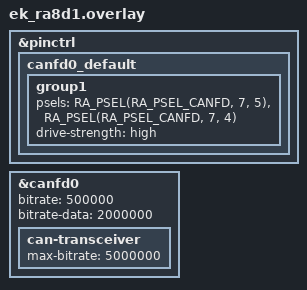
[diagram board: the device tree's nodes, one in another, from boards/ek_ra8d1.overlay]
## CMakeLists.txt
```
# SPDX-License-Identifier: Apache-2.0
#
# can_logger — integrated CAN-FD capture + CLP host link.
# Board target: ek_ra8d1. The CANFD0 pin remap (CTX0=P704 / CRX0=P705) and
# bitrates are applied automatically from boards/ek_ra8d1.overlay.
#
# clp_proto.c / clp_proto.h are shared verbatim with apps/usb_cdc (the CLP
# protocol codec is transport-agnostic by design — see docs/clp_protocol.md).
# They are referenced in place rather than copied so there is a single source
# of truth; clp_uart.c is the UART-specific transport glue (cf. usb_cdc's
# usb_link.c for the CDC-ACM one).

cmake_minimum_required(VERSION 3.28.0)

find_package(Zephyr REQUIRED HINTS $ENV{ZEPHYR_BASE})
project(can_logger)

target_include_directories(app PRIVATE
  include
  ${CMAKE_CURRENT_SOURCE_DIR}/../usb_cdc/include
)
target_sources(app PRIVATE
  src/main.c
  src/can_iface.c
  src/clp_uart.c
  ${CMAKE_CURRENT_SOURCE_DIR}/../usb_cdc/src/clp_proto.c
)
```

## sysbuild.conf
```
# Phase 3 — sysbuild configuration for apps/can_logger.
# Only consumed when the app is built with `west build --sysbuild`; a plain
# `west build apps/can_logger` ignores this file and builds exactly as in
# Phase 2A (no bootloader, links at flash0 base 0x02000000).
#
# Every SB_CONFIG_* symbol below was checked against this checkout:
#   SB_CONFIG_BOOTLOADER_MCUBOOT            -> zephyr/share/sysbuild/images/bootloader/Kconfig
#   SB_CONFIG_MCUBOOT_MODE_OVERWRITE_ONLY   -> same file, choice MCUBOOT_MODE
#   SB_CONFIG_BOOT_SIGNATURE_TYPE_ECDSA_P256-> same file, choice BOOT_SIGNATURE_TYPE
#
# Mode = OVERWRITE_ONLY (not the sysbuild default SWAP_USING_OFFSET) because
# the RA8D1 on-chip code flash (flash0) has write-block-size = 128, and
# MCUboot's bootutil_public.h hard-asserts
#   MCUBOOT_BOOT_MAX_ALIGN >= 8 && <= 32   "for SWAP upgrade modes"
# (CONFIG_MCUBOOT_BOOT_MAX_ALIGN defaults to the chosen flash write-block-size
# -> 128 here). OVERWRITE_ONLY does not trip that assert. See STATE.md.

SB_CONFIG_BOOTLOADER_MCUBOOT=y
SB_CONFIG_MCUBOOT_MODE_OVERWRITE_ONLY=y

# ECDSA P-256 image signing: smaller verify code than RSA-2048 on Cortex-M85,
# and the private PEM that ships with the mcuboot module
# ($ZEPHYR_MCUBOOT_MODULE_DIR/root-ec-p256.pem) is used automatically until we
# supply our own key via SB_CONFIG_BOOT_SIGNATURE_KEY_FILE. This is the hook
# for a project signing key (see STATE.md "MCUboot / SecOC" note).
SB_CONFIG_BOOT_SIGNATURE_TYPE_ECDSA_P256=y
```

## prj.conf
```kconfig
# can_logger — integrated CAN-FD capture + CLP host link (Phase 5 follow-on).
#
# The Phase 2A CAN-FD module (can_iface.c) now feeds the Phase 2C CLP protocol
# (clp_proto.c, shared from apps/usb_cdc) over a UART transport (clp_uart.c).
# Live RX frames go to the host as CLP_MSG_CAN_RX; the host can request a
# transmit with CLP_MSG_CAN_TX. Every symbol below was checked against the
# workspace before being added.
#
#   CONFIG_CAN / _CAN_FD_MODE / _CAN_RENESAS_RA_CANFD -> drivers/can/Kconfig*
#        (unchanged from Phase 2A). NOT CONFIG_CAN_RX_TIMESTAMP — the
#        renesas,ra-canfd driver does not implement it; we software-timestamp
#        in the RX ISR (can_iface.c).
#   CONFIG_COBS   -> lib/utils/Kconfig  (COBS framing, <zephyr/data/cobs.h>)
#   CONFIG_CRC    -> subsys/crc/Kconfig (crc16_ccitt() for CLP CRC-16/X-25).
#        CONFIG_CRC_HW_HANDLER forced off — clp_proto.c uses the SW routine and
#        we don't want the on-chip CRC driver pulled in.
#   CONFIG_RING_BUFFER -> lib/os/Kconfig (tx/rx byte rings in clp_uart.c)
#   CONFIG_UART_INTERRUPT_DRIVEN -> drivers/serial/Kconfig; the uart9 driver is
#        renesas,ra8-uart-sci-b (uart_renesas_ra8_sci_b.c) which implements the
#        fifo_fill / irq_tx_ready / irq_rx_ready / irq_callback_set API.
#   CONFIG_POLL -> kernel/Kconfig (k_poll is not used; k_msgq + k_sem only).

CONFIG_CAN=y
CONFIG_CAN_FD_MODE=y
CONFIG_CAN_RENESAS_RA_CANFD=y

CONFIG_SERIAL=y
CONFIG_UART_INTERRUPT_DRIVEN=y
CONFIG_RING_BUFFER=y
CONFIG_COBS=y
CONFIG_CRC=y
CONFIG_CRC_HW_HANDLER=n

# --- COM12 (J-Link VCOM = uart9) is handed over to raw CLP binary framing ---
# The UART console driver and the UART log backend would both write ASCII onto
# the same wire and corrupt the CLP byte stream, so both are disabled. Zephyr
# logging + printk are routed to SEGGER RTT instead (view with J-Link RTT
# Viewer / `JLinkRTTClient`), which keeps a debug channel without touching COM12.
CONFIG_UART_CONSOLE=n
CONFIG_LOG=y
CONFIG_LOG_DEFAULT_LEVEL=3
CONFIG_LOG_BACKEND_UART=n
CONFIG_USE_SEGGER_RTT=y
CONFIG_LOG_BACKEND_RTT=y
CONFIG_RTT_CONSOLE=y
CONFIG_SEGGER_RTT_BUFFER_SIZE_UP=4096
# Drop log records when no RTT viewer is draining the buffer (headless bench
# runs) instead of stalling on every message.
CONFIG_LOG_BACKEND_RTT_MODE_DROP=y

# clp_uart.c encodes CLP frames (COBS + CRC, up to ~90 B) on the caller stack;
# the CAN RX ISR only does a k_msgq_put, so the heavy work is in threads. 4 KiB
# main stack matches the other apps and covers the boot-time HELLO encode.
CONFIG_MAIN_STACK_SIZE=4096
```

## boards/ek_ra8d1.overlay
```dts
/*
 * App-local devicetree overlay for apps/can_logger on the EK-RA8D1.
 * Zephyr auto-applies <app>/boards/<board>.overlay by filename.
 *
 * Mirrors the project overlay D:/BITS_ASSIGNMENTS/ESD/SITUATIONAL_LEARNING/
 * boards/ek_ra8d1.overlay (kept in sync by hand) and additionally sets the
 * CAN-FD bitrates for this app.
 *
 * CANFD0 pins (see STATE.md "CANFD0 pin decision" + its RETRACTION for the
 * full rationale):
 *     CTX0 (CAN TX, MCU -> transceiver TXD) = P704
 *     CRX0 (CAN RX, transceiver RXD -> MCU) = P705
 * This is the Renesas FSP default pair, and matches the physical breadboard
 * wiring as built.
 *
 * The Phase 1 choice of P203/P202 is RETRACTED (2026-08-31): our part
 * R7FA8D1BHECBD (package PLBG0224GD-A) is the MIPI variant per datasheet
 * Table 1.13, so P202-P205 are permanently MIPI_CL_P/N + MIPI_DL0_P/N and
 * do not exist as GPIO/CANFD pins at all. The earlier "confirmation" read
 * the datasheet's "BGA224 without MIPI" column by mistake.
 *
 * TRADE-OFF ACCEPTED: P704/P705 are RMII0_RX_ER_B / RMII0_CRS_DV_B in the
 * board's ETHERNET-B mux and are bus-switch-routed to the Ethernet PHY in
 * hardware, so CAN-FD and on-chip Ethernet are mutually exclusive on this
 * board. Project decision: sequential use modes (capture over CAN, retrieve
 * over Ethernet afterwards), not simultaneous.
 *
 * Transceiver STB is hard-wired to GND (normal mode), so there is no
 * enable/standby GPIO entry here on purpose.
 */

#include <zephyr/dt-bindings/pinctrl/renesas/pinctrl-ra.h>

&pinctrl {
	/* Overrides the same-named node in
	 * zephyr/boards/renesas/ek_ra8d1/ek_ra8d1-pinctrl.dtsi; psels replaced.
	 *
	 * Encoding verified against pinctrl-ra.h:144 --
	 * RA_PSEL(psel,port,pin) = 1<<13 | psel<<8 | pin<<4 | port<<0,
	 * RA_PSEL_CANFD = 0x10. So P704 -> 0x3047, P705 -> 0x3057.
	 */
	canfd0_default: canfd0_default {
		group1 {
			/* CRX0 CTX0 */
			psels = <RA_PSEL(RA_PSEL_CANFD, 7, 5)>,   /* CRX0 -> P705 */
				<RA_PSEL(RA_PSEL_CANFD, 7, 4)>;   /* CTX0 -> P704 */
			drive-strength = "high";
		};
	};
};

&canfd0 {
	/* Arbitration phase 500 kbit/s, FD data phase 2 Mbit/s — common
	 * automotive CAN-FD rates and safely within any CAN-FD transceiver.
	 * Sample points left unset -> driver auto-selects (87.5% / 80% / 75%).
	 */
	bitrate = <500000>;
	bitrate-data = <2000000>;

	/* Passive external transceiver on the breadboard (STB tied to GND).
	 * max-bitrate documents the data-phase ceiling used for bitrate
	 * validation; tighten to the real transceiver datasheet once known.
	 */
	can-transceiver {
		max-bitrate = <5000000>;
	};
};
```

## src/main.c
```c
/*
 * SPDX-License-Identifier: Apache-2.0
 *
 * can_logger — integrated entry point.
 *
 * Wires the Phase 2A CAN-FD module (can_iface.c) to the Phase 2C CLP protocol
 * (clp_proto.c) over a UART transport (clp_uart.c):
 *
 *     canfd0 RX ISR ──▶ on_can_rx() ──▶ k_msgq ──▶ pump_thread ──▶ CLP_MSG_CAN_RX ──▶ COM12
 *     COM12 ──▶ CLP_MSG_CAN_TX ──▶ on_tx_request() ──▶ can_iface_send() ──▶ canfd0 TX
 *                                                  └─▶ CLP_MSG_CAN_TX_ACK ──▶ COM12
 *     pump_thread also emits CLP_MSG_STATUS ~1 Hz.
 *
 * The RX ISR does only a k_msgq_put so interrupt latency stays low; all CLP
 * encoding happens in pump_thread / rx_thread context.
 *
 * "Interrupt + NVIC" report deliverable: the RX path is canfd0 RX vector
 * (NVIC IRQ 45, prio 12) -> can_iface_rx_isr -> on_can_rx. See can_iface.c.
 */

#include <errno.h>
#include <string.h>

#include <zephyr/kernel.h>
#include <zephyr/logging/log.h>

#include "can_iface.h"
#include "clp_uart.h"

LOG_MODULE_REGISTER(main, LOG_LEVEL_INF);

/* Boot self-transmit: a bench convenience that proves the TX path on power-up.
 * OFF by default: a logger should not inject traffic onto a bus that may not
 * be live yet. With no peer ACKing, the RA controller auto-retransmits (no
 * CAN_MODE_ONE_SHOT on this driver) and one frame becomes a sustained error
 * storm -> BUS_OFF. Set to 1 only for bench TX testing with a peer present.
 */
#define BOOT_TX_SELFTEST 0
/* If BOOT_TX_SELFTEST: CLASSIC frame only (the bench PCAN-USB is classic-only;
 * an FD/BRS frame there storms even harder). Flip to 1 with FD-capable gear.
 */
#define BOOT_TX_USE_FD 0

/* CAN RX ISR -> pump_thread hand-off. 64 * sizeof(canlog_frame) ~= 5 KiB. */
K_MSGQ_DEFINE(can_rx_msgq, sizeof(struct canlog_frame), 64, 4);

static atomic_t stat_rx_msgq_drops;   /* CAN faster than the pump could drain */
static atomic_t stat_tx_requests;     /* CLP_MSG_CAN_TX accepted from the host */

/* -------------------------------------------------------------------------- */
/* Flag translation: Zephyr CAN_FRAME_* <-> CLP_CANF_*                         */
/*                                                                            */
/* clp_proto.h's comment claims the bit positions line up 1:1 with Zephyr's,  */
/* but they do NOT (CAN_FRAME_IDE=BIT(0) vs CLP_CANF_IDE=BIT(3), etc.). The    */
/* usb_cdc self-test never noticed because it only round-trips CLP<->CLP. An   */
/* explicit map is the integration point where that matters.                  */
/* -------------------------------------------------------------------------- */

static uint8_t clp_flags_from_can(uint8_t canf)
{
	uint8_t o = 0U;

	if (canf & CAN_FRAME_FDF) {
		o |= CLP_CANF_FDF;
	}
	if (canf & CAN_FRAME_BRS) {
		o |= CLP_CANF_BRS;
	}
	if (canf & CAN_FRAME_ESI) {
		o |= CLP_CANF_ESI;
	}
	if (canf & CAN_FRAME_IDE) {
		o |= CLP_CANF_IDE;
	}
	if (canf & CAN_FRAME_RTR) {
		o |= CLP_CANF_RTR;
	}
	return o;
}

static uint8_t can_flags_from_clp(uint8_t clpf)
{
	uint8_t o = 0U;

	if (clpf & CLP_CANF_FDF) {
		o |= CAN_FRAME_FDF;
	}
	if (clpf & CLP_CANF_BRS) {
		o |= CAN_FRAME_BRS;
	}
	if (clpf & CLP_CANF_ESI) {
		o |= CAN_FRAME_ESI;
	}
	if (clpf & CLP_CANF_IDE) {
		o |= CAN_FRAME_IDE;
	}
	if (clpf & CLP_CANF_RTR) {
		o |= CAN_FRAME_RTR;
	}
	return o;
}

/* -------------------------------------------------------------------------- */
/* CAN RX  (ISR context - keep it to the k_msgq_put)                          */
/* -------------------------------------------------------------------------- */

static void on_can_rx(const struct canlog_frame *frame, void *user_data)
{
	ARG_UNUSED(user_data);

	if (k_msgq_put(&can_rx_msgq, frame, K_NO_WAIT) != 0) {
		atomic_inc(&stat_rx_msgq_drops);
	}
}

/* -------------------------------------------------------------------------- */
/* CLP_MSG_CAN_TX from the host  (rx_thread context)                          */
/* -------------------------------------------------------------------------- */

static void on_tx_request(const struct clp_can_frame *req, void *user_data)
{
	ARG_UNUSED(user_data);

	struct canlog_frame tx = {
		.id = req->can_id,
		.dlc = req->dlc,
		.flags = can_flags_from_clp(req->flags),
	};
	const uint8_t n = can_dlc_to_bytes(req->dlc);
	int ret;

	memcpy(tx.data, req->data, MIN(n, (uint8_t)sizeof(tx.data)));

	ret = can_iface_send(&tx, K_MSEC(50));
	if (ret == 0) {
		atomic_inc(&stat_tx_requests);
	} else {
		LOG_WRN("host CAN_TX id=0x%x -> can_iface_send %d", req->can_id, ret);
	}

	struct clp_tx_ack ack = {
		.tag = req->tag,
		.status = (int16_t)ret,
		.timestamp = (uint64_t)k_uptime_ticks(),
	};
	(void)clp_uart_send_tx_ack(&ack);
}

/* -------------------------------------------------------------------------- */
/* Pump thread: msgq -> CLP_MSG_CAN_RX, plus ~1 Hz CLP_MSG_STATUS             */
/* -------------------------------------------------------------------------- */

static void send_status(void)
{
	enum can_state bus_state = CAN_STATE_ERROR_ACTIVE;
	struct can_bus_err_cnt err = { 0 };
	uint32_t tx_frames = 0, tx_drops = 0, crc_err = 0, frm_err = 0;

	(void)can_iface_state(&bus_state, &err);
	clp_uart_get_counters(&tx_frames, &tx_drops, &crc_err, &frm_err);

	struct clp_status st = {
		.bus_state = (uint8_t)bus_state,
		.rx_frames = tx_frames,
		.tx_frames = (uint32_t)atomic_get(&stat_tx_requests),
		.rx_drops = tx_drops + (uint32_t)atomic_get(&stat_rx_msgq_drops),
		.tx_err_cnt = err.tx_err_cnt,
		.rx_err_cnt = err.rx_err_cnt,
	};

	(void)clp_uart_send_status(&st);
}

static void pump_thread(void *a, void *b, void *c)
{
	ARG_UNUSED(a);
	ARG_UNUSED(b);
	ARG_UNUSED(c);

	int64_t last_status = k_uptime_get();
	unsigned int status_ticks = 0;

	for (;;) {
		struct canlog_frame f;

		if (k_msgq_get(&can_rx_msgq, &f, K_MSEC(500)) == 0) {
			struct clp_can_frame cf = {
				.can_id = f.id,
				.flags = clp_flags_from_can(f.flags),
				.dlc = f.dlc,
				.tag = 0U,
				.timestamp = f.timestamp,
			};

			memcpy(cf.data, f.data, sizeof(cf.data));
			(void)clp_uart_send_can_rx(&cf);
		}

		if (k_uptime_get() - last_status >= 1000) {
			last_status = k_uptime_get();
			send_status();
			/* Re-announce every 5 s so a host attaching mid-run
			 * still learns the fw version (HELLO is otherwise
			 * boot-only).
			 */
			if (++status_ticks % 5U == 0U) {
				clp_uart_send_hello();
			}
		}
	}
}

static K_THREAD_STACK_DEFINE(pump_stack, 2048);
static struct k_thread pump_data;

/* -------------------------------------------------------------------------- */

int main(void)
{
	int ret;

	ret = can_iface_init();
	if (ret != 0) {
		LOG_ERR("can_iface_init failed: %d", ret);
		return 0;
	}
	can_iface_set_rx_handler(on_can_rx, NULL);

	ret = clp_uart_init();
	if (ret != 0) {
		LOG_ERR("clp_uart_init failed: %d", ret);
		return 0;
	}
	clp_uart_set_tx_handler(on_tx_request, NULL);

	k_thread_create(&pump_data, pump_stack, K_THREAD_STACK_SIZEOF(pump_stack),
			pump_thread, NULL, NULL, NULL,
			K_PRIO_PREEMPT(8), 0, K_NO_WAIT);
	k_thread_name_set(&pump_data, "clp_pump");

#if BOOT_TX_SELFTEST
	/* Bench-only: prove the TX path on power-up. Needs a peer ACKing. */
	struct canlog_frame boot_tx = {
		.id = 0x123,
		.dlc = 8,
#if BOOT_TX_USE_FD
		.flags = CAN_FRAME_FDF | CAN_FRAME_BRS,
#else
		.flags = 0,
#endif
	};

	for (uint8_t i = 0; i < 8; i++) {
		boot_tx.data[i] = i;
	}

	ret = can_iface_send(&boot_tx, K_MSEC(100));
	if (ret != 0) {
		LOG_WRN("boot self-TX returned %d (no bus / no ACK?)", ret);
	}
#endif

	LOG_INF("can_logger integrated: CAN-FD <-> CLP on the console UART");
	return 0;
}
```

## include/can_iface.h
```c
/*
 * SPDX-License-Identifier: Apache-2.0
 *
 * Phase 2A — self-contained CAN-FD interface for canfd0 on the EK-RA8D1.
 *
 * Wraps the Zephyr native CAN controller API (zephyr/drivers/can.h) for the
 * on-chip Renesas RA CAN-FD controller (compatible "renesas,ra-canfd",
 * channel 0). The transceiver is external and passive (STB hard-wired to
 * GND); pin routing CTX0=P203 / CRX0=P202 comes from the board overlay.
 *
 * Build-only in this phase: no board attached, nothing is flashed or run.
 */

#ifndef CAN_LOGGER_CAN_IFACE_H_
#define CAN_LOGGER_CAN_IFACE_H_

#include <stdint.h>
#include <zephyr/kernel.h>
#include <zephyr/drivers/can.h>

/**
 * @brief One captured/queued CAN(-FD) frame.
 *
 * Deliberately a superset of the fields the university report asks for:
 * ID, DLC, flags, data, timestamp.
 *
 * @note @p data is sized to CAN_MAX_DLEN, which is 64 when CONFIG_CAN_FD_MODE
 *       is enabled and 8 otherwise (see zephyr/include/zephyr/drivers/can.h).
 * @note @p timestamp is a *software* timestamp (k_uptime_ticks()) sampled
 *       inside the RX interrupt callback. The renesas,ra-canfd driver does
 *       not implement CONFIG_CAN_RX_TIMESTAMP, so no hardware bit-time
 *       timestamp is available on this SoC.
 */
struct canlog_frame {
	/** Standard (<= CAN_STD_ID_MASK) or extended (<= CAN_EXT_ID_MASK) ID. */
	uint32_t id;
	/** Raw Data Length Code. Byte count = can_dlc_to_bytes(dlc). */
	uint8_t dlc;
	/** Frame flags: CAN_FRAME_IDE | _RTR | _FDF | _BRS | _ESI. */
	uint8_t flags;
	/** Payload. Valid bytes = can_dlc_to_bytes(dlc). */
	uint8_t data[CAN_MAX_DLEN];
	/** k_uptime_ticks() captured in the RX ISR callback. */
	uint64_t timestamp;
};

/**
 * @brief RX handler, invoked from the CAN RX interrupt callback (ISR context).
 *
 * Keep it short and non-blocking. See can_iface.c for the "Interrupt + NVIC"
 * notes (canfd0 RX vector = NVIC IRQ 45, priority 12).
 */
typedef void (*canlog_rx_handler_t)(const struct canlog_frame *frame, void *user_data);

/**
 * @brief Configure canfd0 for CAN-FD, install the standard/extended/FD RX
 *        filters and start the controller.
 *
 * @retval 0        on success
 * @retval -ENODEV  canfd0 device not ready
 * @retval -ENOTSUP controller does not advertise CAN_MODE_FD
 * @retval <0       errno from can_set_mode()/can_add_rx_filter()/can_start()
 */
int can_iface_init(void);

/**
 * @brief Register the application RX handler (called in ISR context).
 *
 * @retval 0 always. Pass NULL to detach.
 */
int can_iface_set_rx_handler(canlog_rx_handler_t handler, void *user_data);

/**
 * @brief Queue a frame for transmission on canfd0 (non-blocking).
 *
 * Fills a struct can_frame from @p frame and calls can_send() with an
 * internal completion callback, so this never blocks on bus arbitration.
 *
 * @param frame   frame to send (id/dlc/flags/data are used)
 * @param timeout wait for a free TX mailbox, or K_NO_WAIT / K_FOREVER
 * @retval 0 on success, negative errno from can_send() otherwise
 */
int can_iface_send(const struct canlog_frame *frame, k_timeout_t timeout);

/**
 * @brief Thin pass-through to can_get_state() for canfd0.
 */
int can_iface_state(enum can_state *state, struct can_bus_err_cnt *err_cnt);

#endif /* CAN_LOGGER_CAN_IFACE_H_ */
```

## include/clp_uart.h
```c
/*
 * SPDX-License-Identifier: Apache-2.0
 *
 * CLP transport glue for a plain hardware UART (the J-Link VCOM on COM12,
 * chosen zephyr,console = &uart9 on the EK-RA8D1).
 *
 * Mirrors apps/usb_cdc/src/usb_link.c (the CDC-ACM transport) but for an
 * interrupt-driven SCI UART:
 *   - TX: clp_uart_send_*() encode a COBS-framed CLP frame on the caller's
 *     stack and push the bytes into an outbound ring buffer under a spinlock.
 *     Callable from any context including the CAN RX ISR. Lossy by design:
 *     a full ring drops the frame and bumps a counter, never blocks.
 *   - RX: the UART ISR copies received bytes into an inbound ring and wakes a
 *     worker thread, which feeds clp_parser and forwards decoded
 *     CLP_MSG_CAN_TX requests to the registered handler (thread context).
 *
 * There is no DTR / connect concept on a bare UART, so a HELLO is sent once at
 * init and the caller is expected to emit periodic CLP_MSG_STATUS frames so a
 * host that attaches late can resync (COBS guarantees resync at the next 0x00).
 */

#ifndef CAN_LOGGER_CLP_UART_H_
#define CAN_LOGGER_CLP_UART_H_

#include <stdbool.h>
#include <stdint.h>

#include "clp_proto.h"

#ifdef __cplusplus
extern "C" {
#endif

/** Invoked in worker-thread context for each CLP_MSG_CAN_TX received. */
typedef void (*clp_uart_tx_request_cb_t)(const struct clp_can_frame *req,
					 void *user_data);

/**
 * @brief Take over the console UART, start the RX worker, queue a HELLO.
 *
 * @retval 0        success
 * @retval -ENODEV  the UART device is not ready
 */
int clp_uart_init(void);

/** Register the CLP_MSG_CAN_TX handler. Pass NULL to detach. */
void clp_uart_set_tx_handler(clp_uart_tx_request_cb_t cb, void *user_data);

/**
 * @brief Queue a HELLO frame. Sent once by clp_uart_init(); call again
 *        periodically so a host that attaches mid-run learns the fw version.
 */
void clp_uart_send_hello(void);

/**
 * @brief Queue a received CAN frame for the host as CLP_MSG_CAN_RX.
 *
 * Non-blocking. @retval 0 queued, -ENOSPC dropped (ring full), <0 encode error.
 */
int clp_uart_send_can_rx(const struct clp_can_frame *f);

/** Queue a CLP_MSG_CAN_TX_ACK. Same semantics as clp_uart_send_can_rx(). */
int clp_uart_send_tx_ack(const struct clp_tx_ack *ack);

/** Queue a CLP_MSG_STATUS. Same semantics as clp_uart_send_can_rx(). */
int clp_uart_send_status(const struct clp_status *st);

/** Snapshot of link counters (any pointer may be NULL). */
void clp_uart_get_counters(uint32_t *tx_frames, uint32_t *tx_drops,
			   uint32_t *crc_errors, uint32_t *framing_errors);

#ifdef __cplusplus
}
#endif

#endif /* CAN_LOGGER_CLP_UART_H_ */
```

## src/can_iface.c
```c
/*
 * SPDX-License-Identifier: Apache-2.0
 *
 * Phase 2A — CAN-FD interface module for canfd0 (build-only).
 *
 * All Zephyr CAN API used here was verified against
 * zephyr/include/zephyr/drivers/can.h and the controller driver
 * drivers/can/can_renesas_ra.c in this workspace (not from memory):
 *
 *   struct can_frame  { uint32_t id; uint8_t dlc; uint8_t flags;
 *                       uint16_t timestamp/reserved; uint8_t data[CAN_MAX_DLEN]; ... }
 *   struct can_filter { uint32_t id; uint32_t mask; uint8_t flags; }   // flags: only CAN_FILTER_IDE
 *   int  can_set_mode(const struct device *, can_mode_t);
 *   int  can_start(const struct device *);
 *   int  can_send(const struct device *, const struct can_frame *,
 *                 k_timeout_t, can_tx_callback_t, void *user_data);
 *   int  can_add_rx_filter(const struct device *, can_rx_callback_t,
 *                          void *user_data, const struct can_filter *);   // returns filter_id
 *   int  can_get_capabilities(const struct device *, can_mode_t *);
 *   int  can_get_core_clock(const struct device *, uint32_t *);
 *   int  can_get_state(const struct device *, enum can_state *, struct can_bus_err_cnt *);
 *   typedef void (*can_rx_callback_t)(const struct device *, struct can_frame *, void *);
 *   typedef void (*can_tx_callback_t)(const struct device *, int error, void *);
 */

#include <string.h>

#include <zephyr/kernel.h>
#include <zephyr/device.h>
#include <zephyr/drivers/can.h>
#include <zephyr/logging/log.h>

#include "can_iface.h"

LOG_MODULE_REGISTER(can_iface, LOG_LEVEL_INF);

/*
 * canfd0 is the board's chosen CAN bus:
 *   zephyr,canbus = &canfd0;   (zephyr/boards/renesas/ek_ra8d1/ek_ra8d1.dts)
 * Channel 0, compatible "renesas,ra-canfd". Its interrupts (from
 * zephyr/dts/arm/renesas/ra/ra8/ra8x1.dtsi) are:
 *   err = 43, tx = 44, rx = 45   (all at priority 12)
 */
#define CANFD0_NODE DT_CHOSEN(zephyr_canbus)
BUILD_ASSERT(DT_NODE_HAS_STATUS(CANFD0_NODE, okay),
	     "chosen zephyr,canbus (canfd0) is not enabled");

static const struct device *const canfd0 = DEVICE_DT_GET(CANFD0_NODE);

/* ---------------------------------------------------------------------------
 * "Interrupt + NVIC" deliverable (university report)
 * ---------------------------------------------------------------------------
 * The Renesas RA CAN-FD driver connects the channel-0 RX FIFO vector with:
 *
 *   IRQ_CONNECT(DT_INST_IRQ_BY_NAME(index, rx, irq),          // == 45 for canfd0
 *               DT_INST_IRQ_BY_NAME(index, rx, priority),      // == 12
 *               canfd_common_fifo_rx_isr, NULL, 0);
 *   irq_enable(DT_INST_IRQ_BY_NAME(index, rx, irq));           // enable NVIC line 45
 *
 * (drivers/can/can_renesas_ra.c, CAN_RENESAS_RA_INIT()).
 *
 * On a received frame the Cortex-M85 NVIC takes exception for IRQ 45,
 * canfd_common_fifo_rx_isr() runs, the FSP posts CAN_EVENT_RX_COMPLETE, and
 * the driver calls the callback we registered with can_add_rx_filter() -
 * can_iface_rx_isr() below - still in interrupt context. That callback is
 * this project's interrupt-service path for CAN reception.
 * ------------------------------------------------------------------------- */

static canlog_rx_handler_t rx_handler;
static void *rx_handler_user_data;
static int rx_filter_ids[3] = { -1, -1, -1 };

/* RX interrupt callback (ISR context - keep it short, no blocking calls). */
static void can_iface_rx_isr(const struct device *dev, struct can_frame *frame, void *user_data)
{
	ARG_UNUSED(dev);
	ARG_UNUSED(user_data);

	canlog_rx_handler_t handler = rx_handler;

	if (handler == NULL) {
		return;
	}

	struct canlog_frame out = {
		.id = frame->id,
		.dlc = frame->dlc,
		.flags = frame->flags,
		/* Software timestamp: the renesas,ra-canfd driver does not
		 * implement CONFIG_CAN_RX_TIMESTAMP, so frame->timestamp is
		 * meaningless. k_uptime_ticks() is ISR-safe.
		 */
		.timestamp = (uint64_t)k_uptime_ticks(),
	};

	const uint8_t len = can_dlc_to_bytes(frame->dlc);

	memcpy(out.data, frame->data, MIN(len, (uint8_t)sizeof(out.data)));

	handler(&out, rx_handler_user_data);
}

/* TX completion callback (ISR context). Non-blocking send path. */
static void can_iface_tx_done(const struct device *dev, int error, void *user_data)
{
	ARG_UNUSED(dev);
	ARG_UNUSED(user_data);

	if (error != 0) {
		LOG_WRN("CAN TX completion error: %d", error);
	}
}

int can_iface_set_rx_handler(canlog_rx_handler_t handler, void *user_data)
{
	/* Pointer-sized stores; the RX ISR reads a local snapshot of
	 * rx_handler first. Set this before traffic starts.
	 */
	rx_handler_user_data = user_data;
	rx_handler = handler;
	return 0;
}

int can_iface_send(const struct canlog_frame *frame, k_timeout_t timeout)
{
	if (frame == NULL) {
		return -EINVAL;
	}

	struct can_frame tx = {
		.id = frame->id,
		.dlc = frame->dlc,
		.flags = frame->flags,
	};

	const uint8_t len = can_dlc_to_bytes(frame->dlc);

	memcpy(tx.data, frame->data, MIN(len, (uint8_t)sizeof(tx.data)));

	/* Non-blocking: a non-NULL callback makes can_send() return as soon as
	 * the frame is queued (zephyr/include/zephyr/drivers/can.h).
	 */
	return can_send(canfd0, &tx, timeout, can_iface_tx_done, NULL);
}

int can_iface_state(enum can_state *state, struct can_bus_err_cnt *err_cnt)
{
	return can_get_state(canfd0, state, err_cnt);
}

int can_iface_init(void)
{
	int ret;
	uint32_t core_clock = 0;
	can_mode_t caps = 0;

	if (!device_is_ready(canfd0)) {
		LOG_ERR("canfd0 device not ready");
		return -ENODEV;
	}

	ret = can_get_capabilities(canfd0, &caps);
	if (ret != 0) {
		LOG_ERR("can_get_capabilities: %d", ret);
		return ret;
	}
	if ((caps & CAN_MODE_FD) == 0) {
		LOG_ERR("canfd0 does not advertise CAN_MODE_FD (caps=0x%08x)", caps);
		return -ENOTSUP;
	}

	/* CAN-FD, normal (not loopback/listen-only). Bitrates come from the
	 * devicetree (bitrate / bitrate-data in boards/ek_ra8d1.overlay), so
	 * no can_set_bitrate() call is needed here.
	 */
	ret = can_set_mode(canfd0, CAN_MODE_FD);
	if (ret != 0) {
		LOG_ERR("can_set_mode(CAN_MODE_FD): %d", ret);
		return ret;
	}

	/*
	 * RX filters. In the Zephyr CAN API a filter is {id, mask, flags} and
	 * the only filter flag is CAN_FILTER_IDE (standard vs extended ID) -
	 * "CAN-FD" is a per-frame property (CAN_FRAME_FDF), not a filter
	 * criterion. So FD frames are delivered through whichever of these
	 * filters matches, once the controller is in CAN_MODE_FD.
	 *
	 * The renesas,ra-canfd driver evaluates filters in registration order
	 * and stops at the first match (drivers/can/can_renesas_ra.c:
	 * can_renesas_ra_call_rx_cb), so the specific filter is added before
	 * the catch-alls.
	 */
	static const struct can_filter filters[3] = {
		/* [0] targeted example: standard IDs 0x100..0x1FF (diagnostic
		 *     range) - also catches FD frames in that range.
		 */
		{ .id = 0x100, .mask = 0x700, .flags = 0 },
		/* [1] catch-all standard (11-bit) IDs, classic + FD. */
		{ .id = 0, .mask = 0, .flags = 0 },
		/* [2] catch-all extended (29-bit) IDs, classic + FD. */
		{ .id = 0, .mask = 0, .flags = CAN_FILTER_IDE },
	};

	for (int i = 0; i < (int)ARRAY_SIZE(filters); i++) {
		ret = can_add_rx_filter(canfd0, can_iface_rx_isr, NULL, &filters[i]);
		if (ret < 0) {
			LOG_ERR("can_add_rx_filter[%d]: %d", i, ret);
			return ret;
		}
		rx_filter_ids[i] = ret;
	}

	ret = can_start(canfd0);
	if (ret != 0) {
		LOG_ERR("can_start: %d", ret);
		return ret;
	}

	if (can_get_core_clock(canfd0, &core_clock) == 0) {
		LOG_INF("canfd0 started: CAN-FD, core clock %u Hz, RX IRQ 45 (NVIC)",
			core_clock);
	} else {
		LOG_INF("canfd0 started: CAN-FD, RX IRQ 45 (NVIC)");
	}

	return 0;
}
```

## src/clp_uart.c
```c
/*
 * SPDX-License-Identifier: Apache-2.0
 *
 * CLP <-> hardware-UART transport glue. See clp_uart.h for the model.
 *
 * Adapted from apps/usb_cdc/src/usb_link.c. The differences that matter:
 *   - The device is the chosen console UART (uart9 / J-Link VCOM / COM12),
 *     driven through the interrupt API of uart_renesas_ra8_sci_b.c.
 *   - That callback is a *true ISR* (unlike the CDC-ACM one, which the USB
 *     stack services from a workqueue), so the ISR does the minimum — copy
 *     RX bytes into a ring, drain the TX ring — and a worker thread runs the
 *     CLP parser and the inbound CAN_TX dispatch.
 *   - No DTR/VBUS: the link is always "up". HELLO is sent once at init.
 */

#include <errno.h>
#include <string.h>

#include <zephyr/device.h>
#include <zephyr/devicetree.h>
#include <zephyr/drivers/uart.h>
#include <zephyr/kernel.h>
#include <zephyr/logging/log.h>
#include <zephyr/sys/ring_buffer.h>

#include "clp_uart.h"

LOG_MODULE_REGISTER(clp_uart, LOG_LEVEL_INF);

#define CLP_UART_FW_VERSION "can_logger clp-uart v0.1"

/* The CLP wire is the console UART. UART_CONSOLE is disabled in prj.conf so
 * nothing else owns this device's IRQ.
 */
#define CLP_UART_NODE DT_CHOSEN(zephyr_console)
BUILD_ASSERT(DT_NODE_HAS_STATUS(CLP_UART_NODE, okay),
	     "chosen zephyr,console UART is not enabled");

static const struct device *const uart_dev = DEVICE_DT_GET(CLP_UART_NODE);

/* Outbound: encoded CLP bytes waiting for the TX ISR. 2 KiB matches usb_link.
 * At 115200 baud a full ring drains in ~180 ms; under sustained CAN load the
 * host-not-draining case is handled by dropping + counting (tx_drops).
 */
#define TX_RING_SIZE 2048
RING_BUF_DECLARE(tx_rb, TX_RING_SIZE);
static struct k_spinlock tx_lock;

/* Inbound: raw bytes from the RX ISR, consumed by rx_thread. Host -> device
 * traffic is only occasional CAN_TX commands, so this stays small.
 */
#define RX_RING_SIZE 512
RING_BUF_DECLARE(rx_rb, RX_RING_SIZE);
static struct k_spinlock rx_lock;
static K_SEM_DEFINE(rx_sem, 0, 1);

#define ISR_CHUNK 64

static struct clp_parser parser;

static clp_uart_tx_request_cb_t tx_req_cb;
static void *tx_req_cb_data;

static uint8_t tx_seq;

/* Counters, host-visible via CLP_MSG_STATUS / clp_uart_get_counters(). */
static atomic_t stat_tx_frames;
static atomic_t stat_tx_drops;

/* -------------------------------------------------------------------------- */
/* Outbound                                                                   */
/* -------------------------------------------------------------------------- */

static int tx_push(const uint8_t *wire, size_t len)
{
	k_spinlock_key_t key;
	uint32_t wrote;

	key = k_spin_lock(&tx_lock);
	if (ring_buf_space_get(&tx_rb) < len) {
		k_spin_unlock(&tx_lock, key);
		atomic_inc(&stat_tx_drops);
		return -ENOSPC;
	}
	wrote = ring_buf_put(&tx_rb, wire, len);
	k_spin_unlock(&tx_lock, key);

	if (wrote != len) {
		atomic_inc(&stat_tx_drops);
		return -ENOSPC;
	}

	uart_irq_tx_enable(uart_dev);
	return 0;
}

int clp_uart_send_can_rx(const struct clp_can_frame *f)
{
	uint8_t wire[CLP_MAX_WIRE];
	int n;

	n = clp_encode_can_frame(CLP_MSG_CAN_RX, tx_seq++, f, wire, sizeof(wire));
	if (n < 0) {
		return n;
	}

	n = tx_push(wire, (size_t)n);
	if (n == 0) {
		atomic_inc(&stat_tx_frames);
	}
	return n;
}

int clp_uart_send_tx_ack(const struct clp_tx_ack *ack)
{
	uint8_t wire[CLP_MAX_WIRE];
	int n = clp_encode_tx_ack(tx_seq++, ack, wire, sizeof(wire));

	if (n < 0) {
		return n;
	}
	return tx_push(wire, (size_t)n);
}

int clp_uart_send_status(const struct clp_status *st)
{
	uint8_t wire[CLP_MAX_WIRE];
	int n = clp_encode_status(tx_seq++, st, wire, sizeof(wire));

	if (n < 0) {
		return n;
	}
	return tx_push(wire, (size_t)n);
}

void clp_uart_send_hello(void)
{
	uint8_t wire[CLP_MAX_WIRE];
	int n = clp_encode_hello(tx_seq++, CLP_UART_FW_VERSION,
				 wire, sizeof(wire));

	if (n > 0) {
		(void)tx_push(wire, (size_t)n);
	}
}

/* -------------------------------------------------------------------------- */
/* Inbound - CLP frame dispatch (rx_thread context)                           */
/* -------------------------------------------------------------------------- */

static void on_clp_frame(uint8_t type, uint8_t seq, const uint8_t *payload,
			 uint16_t len, void *user_data)
{
	ARG_UNUSED(seq);
	ARG_UNUSED(user_data);

	switch (type) {
	case CLP_MSG_CAN_TX: {
		struct clp_can_frame req;

		if (clp_decode_can_frame(payload, len, &req) != 0) {
			LOG_WRN("CAN_TX decode failed (len %u)", len);
			return;
		}
		if (tx_req_cb != NULL) {
			tx_req_cb(&req, tx_req_cb_data);
		}
		break;
	}
	default:
		LOG_DBG("ignoring inbound CLP type 0x%02x", type);
		break;
	}
}

/* -------------------------------------------------------------------------- */
/* UART ISR - minimal: shuttle bytes between the FIFO and the rings           */
/* -------------------------------------------------------------------------- */

static void uart_isr(const struct device *dev, void *user_data)
{
	ARG_UNUSED(user_data);

	while (true) {
		uart_irq_update(dev);
		if (uart_irq_is_pending(dev) <= 0) {
			break;
		}

		if (uart_irq_rx_ready(dev)) {
			uint8_t buf[ISR_CHUNK];
			int n = uart_fifo_read(dev, buf, sizeof(buf));

			if (n > 0) {
				k_spinlock_key_t key = k_spin_lock(&rx_lock);

				/* Drop on overflow - inbound is low volume; a
				 * lost CAN_TX command is not fatal.
				 */
				(void)ring_buf_put(&rx_rb, buf, (uint32_t)n);
				k_spin_unlock(&rx_lock, key);
				k_sem_give(&rx_sem);
			}
		}

		if (uart_irq_tx_ready(dev)) {
			uint8_t buf[ISR_CHUNK];
			k_spinlock_key_t key = k_spin_lock(&tx_lock);
			uint32_t n = ring_buf_get(&tx_rb, buf, sizeof(buf));

			k_spin_unlock(&tx_lock, key);

			if (n == 0) {
				uart_irq_tx_disable(dev);
			} else {
				int sent = uart_fifo_fill(dev, buf, (int)n);

				if (sent < (int)n) {
					/* Return the tail for the next IRQ. */
					key = k_spin_lock(&tx_lock);
					ring_buf_put(&tx_rb, &buf[sent],
						     n - (uint32_t)sent);
					k_spin_unlock(&tx_lock, key);
				}
			}
		}
	}
}

/* -------------------------------------------------------------------------- */
/* RX worker thread - run the CLP parser off the ISR                          */
/* -------------------------------------------------------------------------- */

static void rx_thread(void *a, void *b, void *c)
{
	ARG_UNUSED(a);
	ARG_UNUSED(b);
	ARG_UNUSED(c);

	for (;;) {
		uint8_t buf[ISR_CHUNK];
		uint32_t n;

		k_sem_take(&rx_sem, K_FOREVER);

		do {
			k_spinlock_key_t key = k_spin_lock(&rx_lock);

			n = ring_buf_get(&rx_rb, buf, sizeof(buf));
			k_spin_unlock(&rx_lock, key);

			if (n > 0) {
				(void)clp_parser_feed(&parser, buf, n);
			}
		} while (n > 0);
	}
}

static K_THREAD_STACK_DEFINE(rx_thread_stack, 1536);
static struct k_thread rx_thread_data;

/* -------------------------------------------------------------------------- */
/* Public                                                                     */
/* -------------------------------------------------------------------------- */

void clp_uart_set_tx_handler(clp_uart_tx_request_cb_t cb, void *user_data)
{
	tx_req_cb = cb;
	tx_req_cb_data = user_data;
}

void clp_uart_get_counters(uint32_t *tx_frames, uint32_t *tx_drops,
			   uint32_t *crc_errors, uint32_t *framing_errors)
{
	if (tx_frames != NULL) {
		*tx_frames = (uint32_t)atomic_get(&stat_tx_frames);
	}
	if (tx_drops != NULL) {
		*tx_drops = (uint32_t)atomic_get(&stat_tx_drops);
	}
	if (crc_errors != NULL) {
		*crc_errors = parser.crc_errors;
	}
	if (framing_errors != NULL) {
		*framing_errors = parser.framing_errors;
	}
}

int clp_uart_init(void)
{
	if (!device_is_ready(uart_dev)) {
		LOG_ERR("console UART not ready");
		return -ENODEV;
	}

	clp_parser_init(&parser, on_clp_frame, NULL);

	uart_irq_rx_disable(uart_dev);
	uart_irq_tx_disable(uart_dev);
	uart_irq_callback_set(uart_dev, uart_isr);

	k_thread_create(&rx_thread_data, rx_thread_stack,
			K_THREAD_STACK_SIZEOF(rx_thread_stack),
			rx_thread, NULL, NULL, NULL,
			K_PRIO_PREEMPT(7), 0, K_NO_WAIT);
	k_thread_name_set(&rx_thread_data, "clp_uart_rx");

	uart_irq_rx_enable(uart_dev);

	clp_uart_send_hello();

	LOG_INF("CLP-over-UART up on %s", uart_dev->name);
	return 0;
}
```
